# STM32H7A3ZIT6Q register map
File version: 1.0
Registers are 32-bit, access not given, reset 0x0 unless marked. A register's access mark holds for its fields unless they carry their own. Offsets are from the block's base; [hi:lo] are bit positions; {n}, {i} and the like mark numbered series.

## TAMP
Base 0x58004400
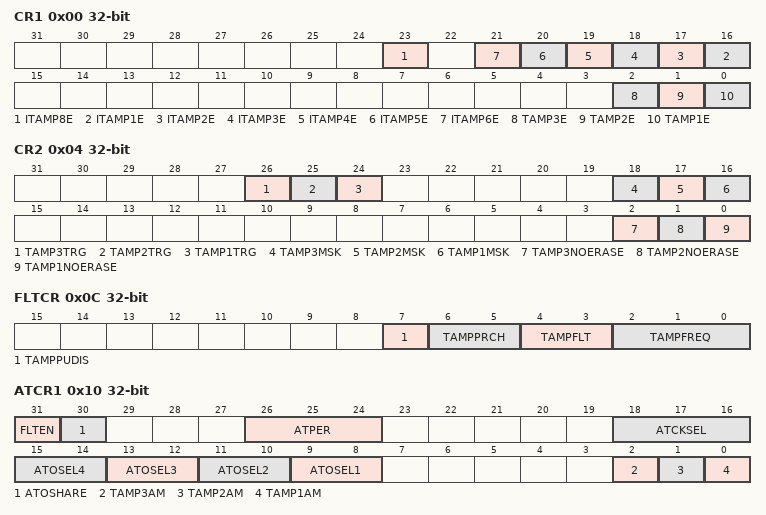
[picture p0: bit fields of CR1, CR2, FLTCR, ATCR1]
0x00 CR1
  [23] ITAMP8E, [n+15] ITAMP{n}E (n=1..6), [2] TAMP3E, [1] TAMP2E, [0] TAMP1E
0x04 CR2
  [26] TAMP3TRG, [25] TAMP2TRG, [24] TAMP1TRG, [18] TAMP3MSK, [17] TAMP2MSK, [16] TAMP1MSK, [2] TAMP3NOERASE, [1] TAMP2NOERASE, [0] TAMP1NOERASE
0x0C FLTCR
  [7] TAMPPUDIS, [6:5] TAMPPRCH, [4:3] TAMPFLT, [2:0] TAMPFREQ
0x10 ATCR1
  [31] FLTEN, [30] ATOSHARE, [26:24] ATPER, [18:16] ATCKSEL, [2n+7:2n+6] ATOSEL{n} (n=1..4), [2] TAMP3AM, [1] TAMP2AM, [0] TAMP1AM
0x14 ATSEEDR
  [31:0] SEED
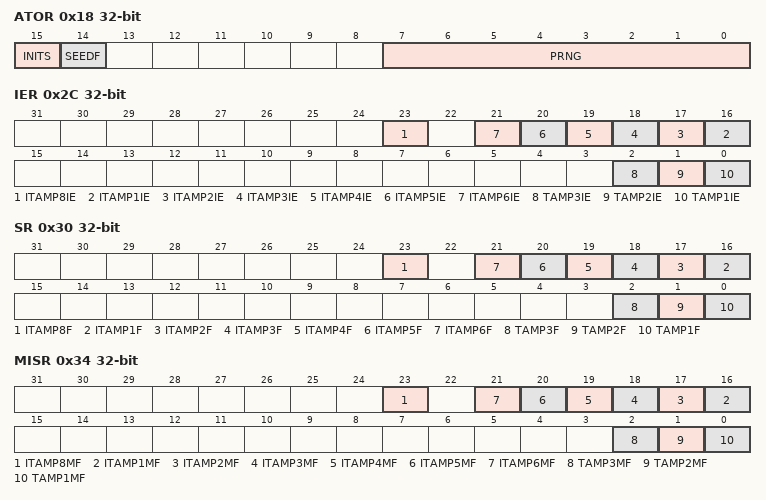
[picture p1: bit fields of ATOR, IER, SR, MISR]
0x18 ATOR
  [15] INITS, [14] SEEDF, [7:0] PRNG
0x2C IER
  [23] ITAMP8IE, [n+15] ITAMP{n}IE (n=1..6), [2] TAMP3IE, [1] TAMP2IE, [0] TAMP1IE
0x30 SR
  [23] ITAMP8F, [n+15] ITAMP{n}F (n=1..6), [2] TAMP3F, [1] TAMP2F, [0] TAMP1F
0x34 MISR
  [23] ITAMP8MF, [n+15] ITAMP{n}MF (n=1..6), [2] TAMP3MF, [1] TAMP2MF, [0] TAMP1MF
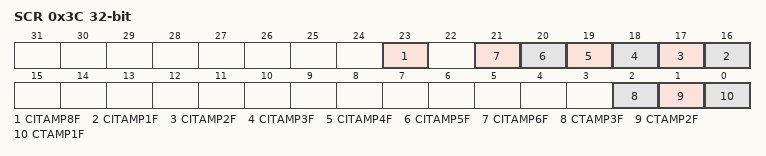
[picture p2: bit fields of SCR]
0x3C SCR
  [23] CITAMP8F, [n+15] CITAMP{n}F (n=1..6), [2] CTAMP3F, [1] CTAMP2F, [0] CTAMP1F
0x40 COUNTR
0x50 CFGR
{0x100+4i} BKP{i}R (i=0..31)

## IWDG1
Base 0x58004800
0x00 KR
  [15:0] KEY
0x04 PR
  [2:0] PR
0x08 RLR
  [11:0] RL
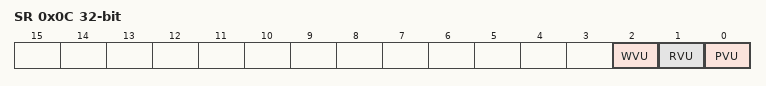
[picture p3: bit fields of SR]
0x0C SR
  [2] WVU, [1] RVU, [0] PVU
0x10 WINR
  [11:0] WIN

## DTS
Base 0x58006800
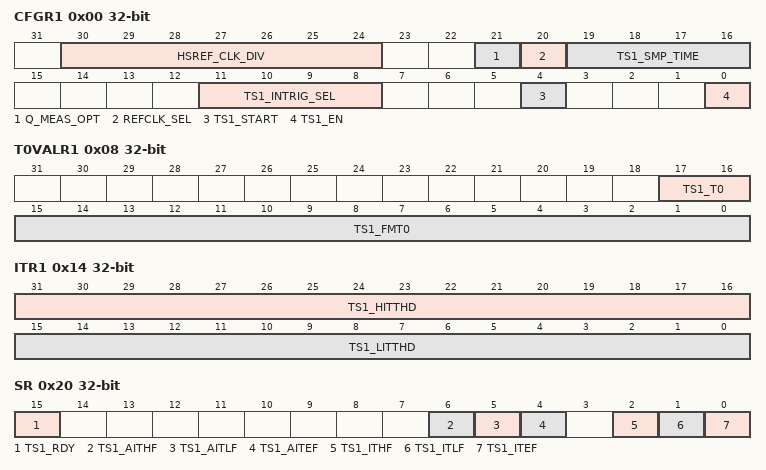
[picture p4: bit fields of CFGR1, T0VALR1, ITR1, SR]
0x00 CFGR1
  [30:24] HSREF_CLK_DIV, [21] Q_MEAS_OPT, [20] REFCLK_SEL, [19:16] TS1_SMP_TIME, [11:8] TS1_INTRIG_SEL, [4] TS1_START, [0] TS1_EN
0x08 T0VALR1
  [17:16] TS1_T0, [15:0] TS1_FMT0
0x10 RAMPVALR
  [15:0] TS1_RAMP_COEFF
0x14 ITR1
  [31:16] TS1_HITTHD, [15:0] TS1_LITTHD
0x1C DR
  [15:0] TS1_MFREQ
0x20 SR
  [15] TS1_RDY, [6] TS1_AITHF, [5] TS1_AITLF, [4] TS1_AITEF, [2] TS1_ITHF, [1] TS1_ITLF, [0] TS1_ITEF
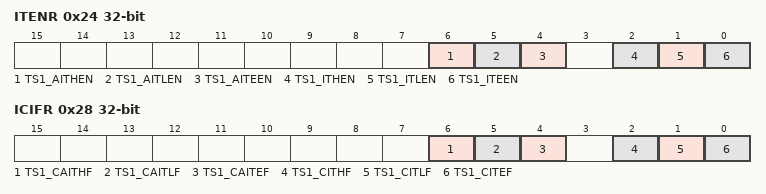
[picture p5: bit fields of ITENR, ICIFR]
0x24 ITENR
  [6] TS1_AITHEN, [5] TS1_AITLEN, [4] TS1_AITEEN, [2] TS1_ITHEN, [1] TS1_ITLEN, [0] TS1_ITEEN
0x28 ICIFR
  [6] TS1_CAITHF, [5] TS1_CAITLF, [4] TS1_CAITEF, [2] TS1_CITHF, [1] TS1_CITLF, [0] TS1_CITEF
0x2C OR

## GPIOA
Base 0x58020000
Same registers: GPIOB 0x58020400, GPIOC 0x58020800, GPIOD 0x58020C00, GPIOE 0x58021000, GPIOF 0x58021400, GPIOG 0x58021800, GPIOH 0x58021C00, GPIOI 0x58022000, GPIOJ 0x58022400, GPIOK 0x58022800
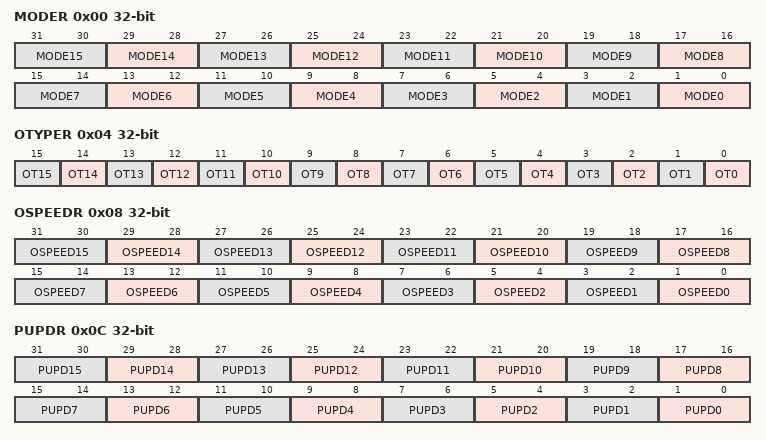
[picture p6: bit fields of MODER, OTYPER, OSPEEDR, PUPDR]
0x00 MODER
  [2n+1:2n] MODE{n} (n=0..15)
0x04 OTYPER
  [n] OT{n} (n=0..15)
0x08 OSPEEDR
  [2n+1:2n] OSPEED{n} (n=0..15)
0x0C PUPDR
  [2n+1:2n] PUPD{n} (n=0..15)
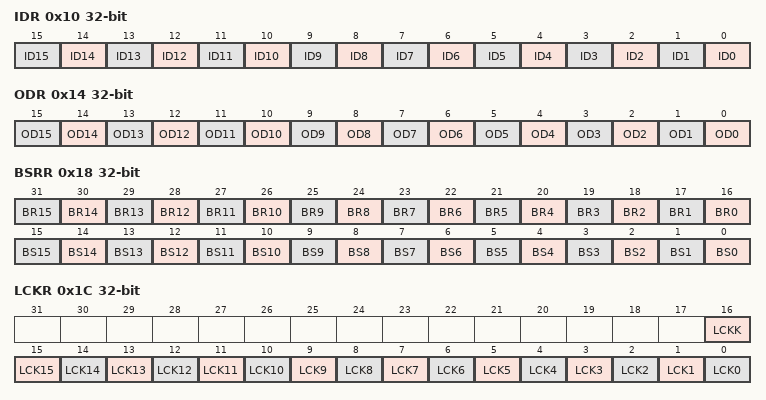
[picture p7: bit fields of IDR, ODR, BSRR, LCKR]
0x10 IDR
  [n] ID{n} (n=0..15)
0x14 ODR
  [n] OD{n} (n=0..15)
0x18 BSRR
  [n+16] BR{n} (n=0..15), [n] BS{n} (n=0..15)
0x1C LCKR
  [16] LCKK, [n] LCK{n} (n=0..15)
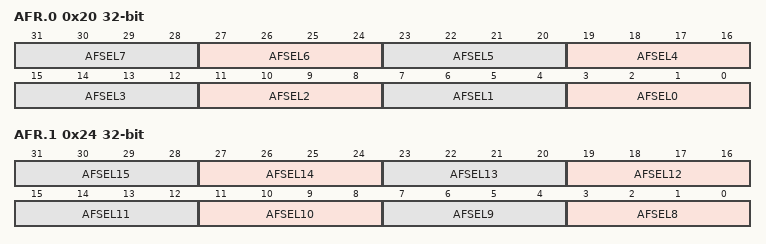
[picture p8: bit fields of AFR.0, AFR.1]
0x20 AFR.0
  [4n+3:4n] AFSEL{n} (n=0..7)
0x24 AFR.1
  [4n-29:4n-32] AFSEL{n} (n=8..15)

## PWR
Base 0x58024800
0x00 CR1
  [27] SRDRAMSO, [26] HSITFSO, [25] GFXSO, [24] ITCMSO, [23] AHBRAM2SO, [22] AHBRAM1SO, [21] AXIRAM3SO, [20] AXIRAM2SO, [19] AXIRAM1SO, [18] ALS_LEV2, [18:17] ALS_LEV3, [16] AVDEN, [15:14] SVOS, [13] AVD_READY, [12] BOOSTE, [9] FLPS, [8] DBP, [7] PLS_LEV4, [7:6] PLS_LEV6, [7:5] PLS_LEV7, [4] PVDEN, [0] LPDS
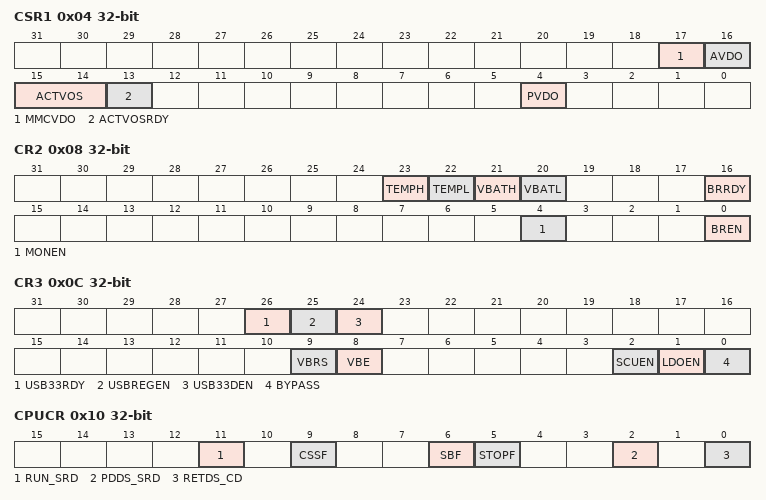
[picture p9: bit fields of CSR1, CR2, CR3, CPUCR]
0x04 CSR1
  [17] MMCVDO, [16] AVDO, [15:14] ACTVOS, [13] ACTVOSRDY, [4] PVDO
0x08 CR2
  [23] TEMPH, [22] TEMPL, [21] VBATH, [20] VBATL, [16] BRRDY, [4] MONEN, [0] BREN
0x0C CR3
  [26] USB33RDY, [25] USBREGEN, [24] USB33DEN, [9] VBRS, [8] VBE, [2] SCUEN, [1] LDOEN, [0] BYPASS
0x10 CPUCR
  [11] RUN_SRD, [9] CSSF, [6] SBF, [5] STOPF, [2] PDDS_SRD, [0] RETDS_CD
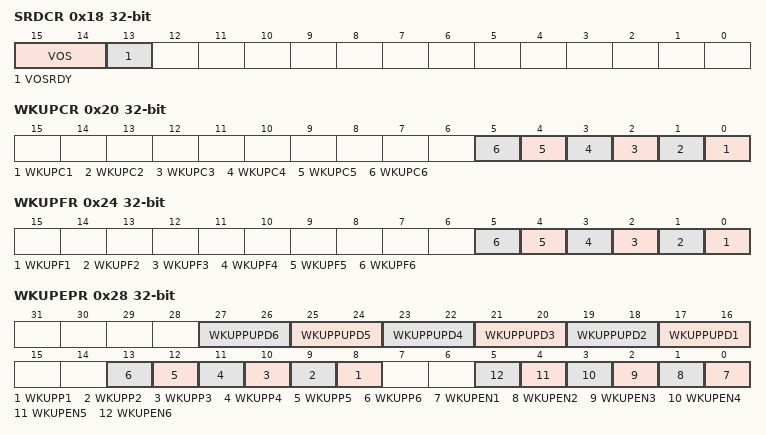
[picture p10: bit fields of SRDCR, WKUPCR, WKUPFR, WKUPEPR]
0x18 SRDCR
  [15:14] VOS, [13] VOSRDY
0x20 WKUPCR
  [n-1] WKUPC{n} (n=1..6)
0x24 WKUPFR
  [n-1] WKUPF{n} (n=1..6)
0x28 WKUPEPR
  [2n+15:2n+14] WKUPPUPD{n} (n=1..6), [n+7] WKUPP{n} (n=1..6), [n-1] WKUPEN{n} (n=1..6)

## DBGMCU
Base 0x5C001000
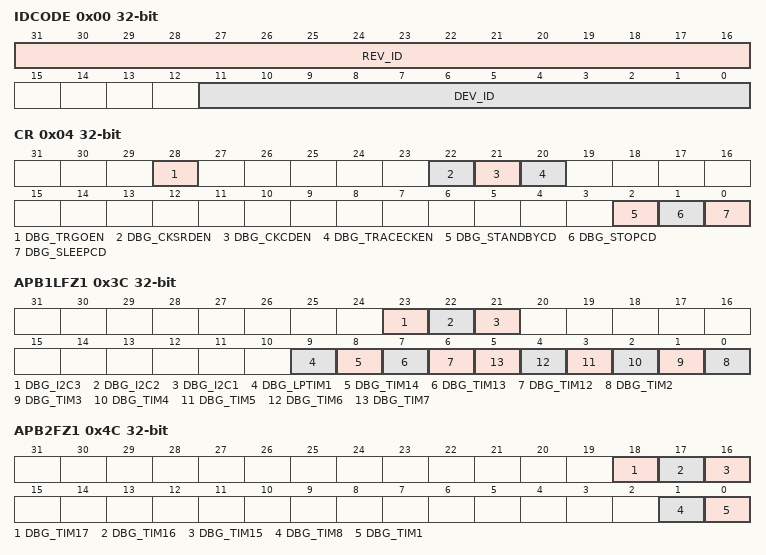
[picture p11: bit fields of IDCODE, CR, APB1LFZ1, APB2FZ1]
0x00 IDCODE
  [31:16] REV_ID, [11:0] DEV_ID
0x04 CR
  [28] DBG_TRGOEN, [22] DBG_CKSRDEN, [21] DBG_CKCDEN, [20] DBG_TRACECKEN, [2] DBG_STANDBYCD, [1] DBG_STOPCD, [0] DBG_SLEEPCD
0x34 APB3FZ1
  [6] DBG_WWDG1
0x3C APB1LFZ1
  [23] DBG_I2C3, [22] DBG_I2C2, [21] DBG_I2C1, [9] DBG_LPTIM1, [8] DBG_TIM14, [7] DBG_TIM13, [6] DBG_TIM12, [n-2] DBG_TIM{n} (n=2..7)
0x44 APB1HFZ1
0x4C APB2FZ1
  [18] DBG_TIM17, [17] DBG_TIM16, [16] DBG_TIM15, [1] DBG_TIM8, [0] DBG_TIM1
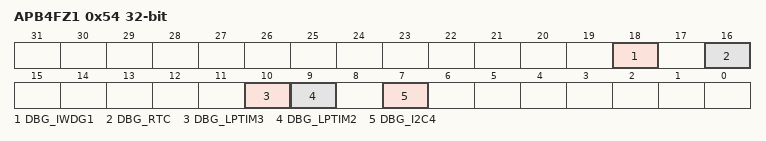
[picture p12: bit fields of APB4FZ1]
0x54 APB4FZ1
  [18] DBG_IWDG1, [16] DBG_RTC, [10] DBG_LPTIM3, [9] DBG_LPTIM2, [7] DBG_I2C4
